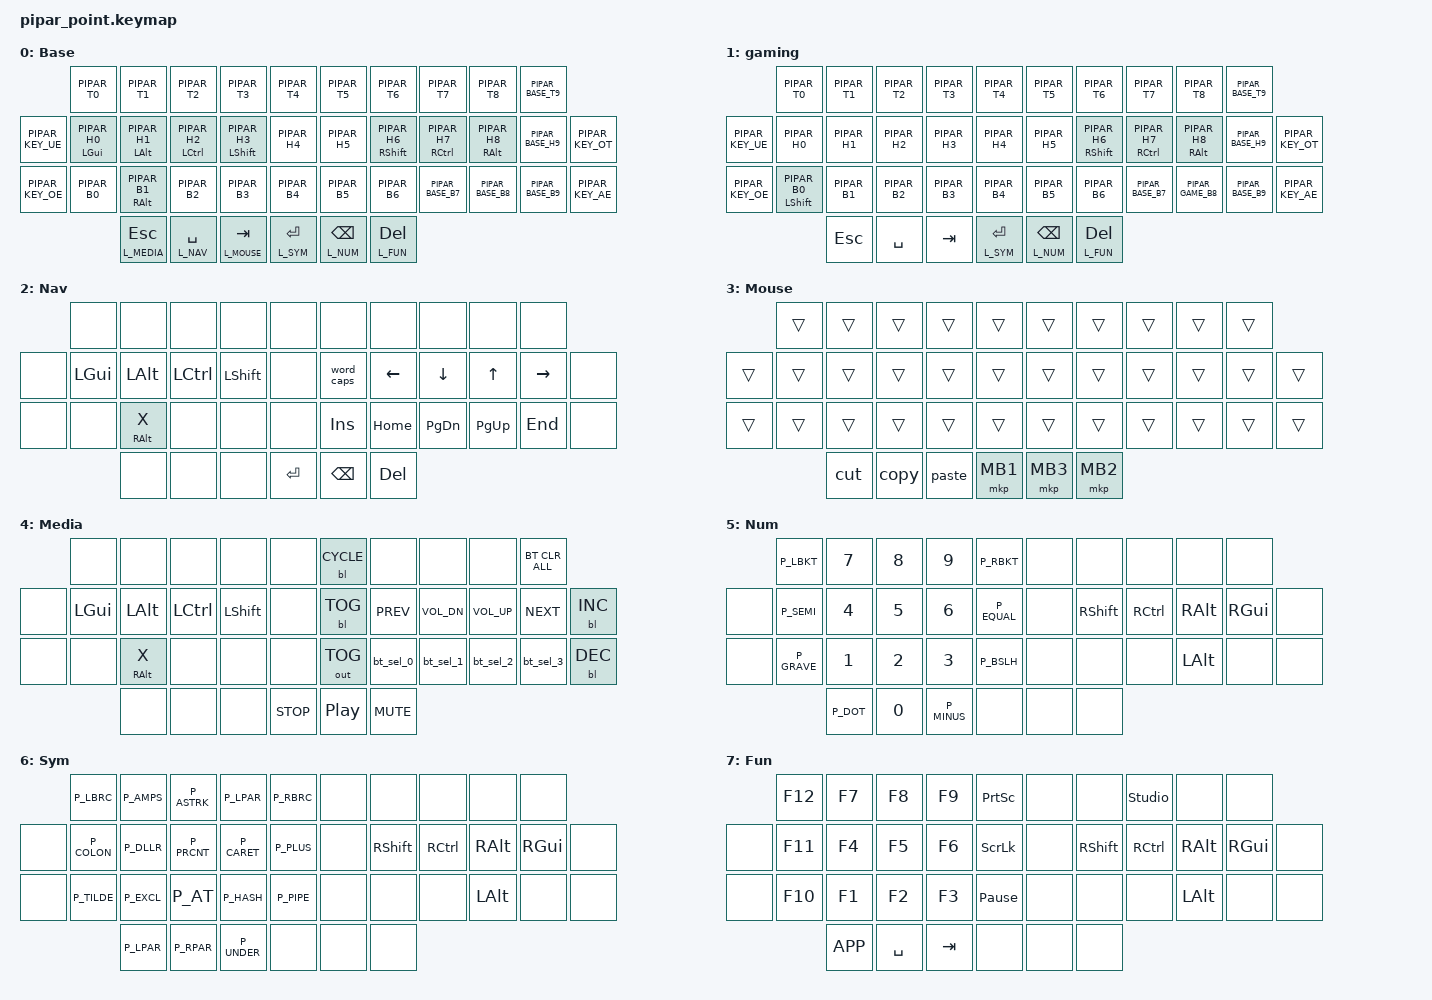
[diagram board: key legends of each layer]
#include <behaviors.dtsi>
#include <dt-bindings/zmk/keys.h>
#include <dt-bindings/zmk/outputs.h>
#include <dt-bindings/zmk/bt.h>
#include <dt-bindings/zmk/backlight.h>
#include <behaviors/unicode.dtsi>
#include "include/keymap_helper.h"
#include <pipar/keymap_variant.h>
#include <pipar/estonian.dtsi>

#ifdef PIPAR_POINT_TRACKPOINT
    #include "include/mouse_tp.dtsi"
    #define U_TOG_TP_SET &tog MOUSE_TP_SET
#else
    #define U_TOG_TP_SET &none
#endif
#include <dt-bindings/zmk/pointing.h>

&uc {
    default-mode = <PIPAR_UC_MODE>;
    minimum-length = <PIPAR_UC_MIN_LENGTH>;
    win-compose-key = <RALT>;
};

/ {

    macros {
        cut: cut {
            compatible = "zmk,behavior-macro";
            #binding-cells = <0>;
            bindings = <&kp PIPAR_CUT>;
        };

        copy: copy {
            compatible = "zmk,behavior-macro";
            #binding-cells = <0>;
            bindings = <&kp PIPAR_COPY>;
        };

        paste: paste {
            compatible = "zmk,behavior-macro";
            #binding-cells = <0>;
            bindings = <&kp PIPAR_PASTE>;
        };

        macro_bt_sel_0: macro_bt_sel_0 {
            compatible = "zmk,behavior-macro";
            #binding-cells = <0>;
            wait-ms = <0>;
            bindings = <&bt BT_SEL 0 &bt BT_CLR>;
        };

        macro_bt_sel_1: macro_bt_sel_1 {
            compatible = "zmk,behavior-macro";
            #binding-cells = <0>;
            wait-ms = <0>;
            bindings = <&bt BT_SEL 1 &bt BT_CLR>;
        };

        macro_bt_sel_2: macro_bt_sel_2 {
            compatible = "zmk,behavior-macro";
            #binding-cells = <0>;
            wait-ms = <0>;
            bindings = <&bt BT_SEL 2 &bt BT_CLR>;
        };

        macro_bt_sel_3: macro_bt_sel_3 {
            compatible = "zmk,behavior-macro";
            #binding-cells = <0>;
            wait-ms = <0>;
            bindings = <&bt BT_SEL 3 &bt BT_CLR>;
        };

    };

    //    00 01 02 03 04       05 06 07 08 09
    // 10 11 12 13 14 15       16 17 18 19 20 21
    // 22 23 24 25 26 27       28 29 30 31 32 33
    //          34 35 36       37 38 39

    combos {
        compatible = "zmk,combos";
        combo_gaming_cdh {
            timeout-ms = <50>;
            key-positions = <21 33>;
            bindings = <&to L_GAMING_DH>;
            layers = <L_FUN>;
        };
        combo_base_layer {
            timeout-ms = <50>;
            key-positions = <21 33>;
            bindings = <&to L_BASE>;
            layers = <L_GAMING_DH>;
        };
    };

    behaviors {
        hml: homerow_mods_left {
            compatible = "zmk,behavior-hold-tap";
            #binding-cells = <2>;
            flavor = "balanced";
            require-prior-idle-ms = <150>;
            tapping-term-ms = <280>;
            quick-tap-ms = <175>;
            bindings = <&kp>, <&kp>;
            hold-trigger-key-positions = <KEYS_RIGHT KEYS_THUMBS>; // List of keys on the right side of the keyboard
            hold-trigger-on-release;
        };

        hmr: homerow_mods_right {
            compatible = "zmk,behavior-hold-tap";
            #binding-cells = <2>;
            flavor = "balanced";
            require-prior-idle-ms = <150>;
            tapping-term-ms = <280>;
            quick-tap-ms = <175>;
            bindings = <&kp>, <&kp>;
            hold-trigger-key-positions = <KEYS_LEFT KEYS_THUMBS>; // List of keys on the left side of the keyboard
            hold-trigger-on-release;
        };

        bt_sel_0: bluetooth_select_0 {
            compatible = "zmk,behavior-mod-morph";
            #binding-cells = <0>;
            bindings = <&bt BT_SEL 0>, <&macro_bt_sel_0>;
            mods = <(MOD_LSFT|MOD_RSFT)>;
        };

        bt_sel_1: bluetooth_select_1 {
            compatible = "zmk,behavior-mod-morph";
            #binding-cells = <0>;
            bindings = <&bt BT_SEL 1>, <&macro_bt_sel_1>;
            mods = <(MOD_LSFT|MOD_RSFT)>;
        };

        bt_sel_2: bluetooth_select_2 {
            compatible = "zmk,behavior-mod-morph";
            #binding-cells = <0>;
            bindings = <&bt BT_SEL 2>, <&macro_bt_sel_2>;
            mods = <(MOD_LSFT|MOD_RSFT)>;
        };

        bt_sel_3: bluetooth_select_3 {
            compatible = "zmk,behavior-mod-morph";
            #binding-cells = <0>;
            bindings = <&bt BT_SEL 3>, <&macro_bt_sel_3>;
            mods = <(MOD_LSFT|MOD_RSFT)>;
        };

        word_caps: word_caps {
            compatible = "zmk,behavior-mod-morph";
            #binding-cells = <0>;
            bindings = <&caps_word>, <&kp CAPS>;
            mods = <(MOD_LSFT|MOD_RSFT)>;
        };

        

    };

    keymap {
        compatible = "zmk,keymap";

        default_layer {
            display-name = "Base";
            
            // Colemak-DH shown; letters come from PIPAR_T*/H*/B* in pipar/keymap_variant.h
            // |     |  Q  |  W  |  F  |  P  |  B  |   |  J  |  L   |  U  |  Y  |  '  |     |
            // |  Ü  |  A  |  R  |  S  |  T  |  G  |   |  M  |  N   |  E  |  I  |  O  |  Õ  |
            // |  Ö  |  Z  |  X  |  C  |  D  |  V  |   |  K  |  H   |  ,  |  .  |  /  |  Ä  |
            //                   | ESC | SPC | TAB |   | ENT | BSCP | DEL |

            bindings = <
                  &kp PIPAR_T0             &kp PIPAR_T1             &kp PIPAR_T2             &kp PIPAR_T3             &kp PIPAR_T4             &kp PIPAR_T5             &kp PIPAR_T6             &kp PIPAR_T7             &kp PIPAR_T8            PIPAR_BASE_T9
PIPAR_KEY_UE      &hml LGUI PIPAR_H0       &hml LALT PIPAR_H1       &hml LCTRL PIPAR_H2      &hml LSHFT PIPAR_H3      &kp PIPAR_H4             &kp PIPAR_H5             &hmr RSHFT PIPAR_H6      &hmr RCTRL PIPAR_H7      &hmr RALT PIPAR_H8      PIPAR_BASE_H9           PIPAR_KEY_OT
PIPAR_KEY_OE      &kp PIPAR_B0             &hml RALT PIPAR_B1       &kp PIPAR_B2             &kp PIPAR_B3             &kp PIPAR_B4             &kp PIPAR_B5             &kp PIPAR_B6             PIPAR_BASE_B7        PIPAR_BASE_B8         PIPAR_BASE_B9       PIPAR_KEY_AE
                                                      &lt L_MEDIA ESC   &lt L_NAV SPACE   &lt L_MOUSE TAB   &lt L_SYM RET     &lt L_NUM BSPC    &lt L_FUN DEL
            >;
        };

        gaming {
            display-name = PIPAR_GAMING_NAME;

            bindings = <
                  &kp PIPAR_T0             &kp PIPAR_T1             &kp PIPAR_T2             &kp PIPAR_T3             &kp PIPAR_T4             &kp PIPAR_T5             &kp PIPAR_T6             &kp PIPAR_T7             &kp PIPAR_T8            PIPAR_BASE_T9
PIPAR_KEY_UE      &kp PIPAR_H0             &kp PIPAR_H1             &kp PIPAR_H2             &kp PIPAR_H3             &kp PIPAR_H4             &kp PIPAR_H5             &hmr RSHFT PIPAR_H6      &hmr RCTRL PIPAR_H7      &hmr RALT PIPAR_H8      PIPAR_BASE_H9            PIPAR_KEY_OT
PIPAR_KEY_OE      &mt LSHFT PIPAR_B0       &kp PIPAR_B1             &kp PIPAR_B2             &kp PIPAR_B3             &kp PIPAR_B4             &kp PIPAR_B5             &kp PIPAR_B6             PIPAR_BASE_B7        PIPAR_GAME_B8         PIPAR_BASE_B9        PIPAR_KEY_AE
                                                      &kp ESC           &kp SPACE         &kp TAB           &lt L_SYM RET     &lt L_NUM BSPC    &lt L_FUN DEL
            >;
        };

        navigation {
            display-name = "Nav";

            bindings = <
                  &none             &none             &none             &none             &none             &none             &none             &none             &none            &none      
&none             &kp LGUI          &kp LALT          &kp LCTRL         &kp LSHFT         &none             &word_caps        &kp LEFT          &kp DOWN          &kp UP           &kp RIGHT        &none 
&none             &none             &hml RALT X       &none             &none             &none             &kp INSERT        &kp HOME          &kp PAGE_DOWN     &kp PAGE_UP      &kp END          &none 
                                                      &none             &none             &none             &kp RET           &kp BSPC          &kp DEL
            >;
        };

        mouse {
            display-name = "Mouse";

            bindings = <
                  &trans            &trans            &trans            &trans            &trans            &trans            &trans            &trans            &trans            &trans 
&trans            &trans            &trans            &trans            &trans            &trans            &trans            &trans            &trans            &trans            &trans          &trans 
&trans            &trans            &trans            &trans            &trans            &trans            &trans            &trans            &trans            &trans            &trans          &trans 
                                                      &cut              &copy             &paste            &mkp MB1          &mkp MB3          &mkp MB2
            >;
        };

        media {
            display-name = "Media";

            bindings = <
                  &none             &none             &none             &none             &none             &bl BL_CYCLE      &none             &none             &none             &bt BT_CLR_ALL 
&none             &kp LGUI          &kp LALT          &kp LCTRL         &kp LSHFT         &none             &bl BL_TOG        &kp C_PREV        &kp C_VOL_DN      &kp C_VOL_UP      &kp C_NEXT       &bl BL_INC
&none             &none             &hml RALT X       &none             &none             &none             &out OUT_TOG      &bt_sel_0         &bt_sel_1         &bt_sel_2         &bt_sel_3        &bl BL_DEC
                                                      &none             &none             &none             &kp C_STOP        &kp C_PP          &kp C_MUTE
            >;
        };
        
        num {
            display-name = "Num";

            bindings = <
                  P_LBKT            &kp N7            &kp N8            &kp N9            P_RBKT            &none             &none             &none             &none             &none                    
&none             P_SEMI            &kp N4            &kp N5            &kp N6            P_EQUAL           &none             &kp RSHFT         &kp RCTRL         &kp RALT          &kp RGUI         &none 
&none             P_GRAVE           &kp N1            &kp N2            &kp N3            P_BSLH            &none             &none             &none             &kp LALT          &none            &none 
                                                      P_DOT             &kp N0            P_MINUS           &none             &none             &none
            >;
        };

        sym {
            display-name = "Sym";

            bindings = <
                  P_LBRC            P_AMPS            P_ASTRK           P_LPAR            P_RBRC            &none             &none             &none             &none             &none                    
&none             P_COLON           P_DLLR            P_PRCNT           P_CARET           P_PLUS            &none             &kp RSHFT         &kp RCTRL         &kp RALT          &kp RGUI         &none 
&none             P_TILDE           P_EXCL            P_AT              P_HASH            P_PIPE            &none             &none             &none             &kp LALT          &none            &none 
                                                      P_LPAR            P_RPAR            P_UNDER           &none             &none             &none
            >;
        };

        fun {
            display-name = "Fun";

            bindings = <
                  &kp F12           &kp F7            &kp F8            &kp F9            &kp PSCRN         &none             &none             &studio_unlock    &none             &none                    
&none             &kp F11           &kp F4            &kp F5            &kp F6            &kp SLCK          &none             &kp RSHFT         &kp RCTRL         &kp RALT          &kp RGUI         &none 
&none             &kp F10           &kp F1            &kp F2            &kp F3            &kp PAUSE_BREAK   &none             &none             &none             &kp LALT          &none            &none 
                                                      &kp K_APP         &kp SPACE         &kp TAB           &none             &none             &none
            >;
        };

    };
};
